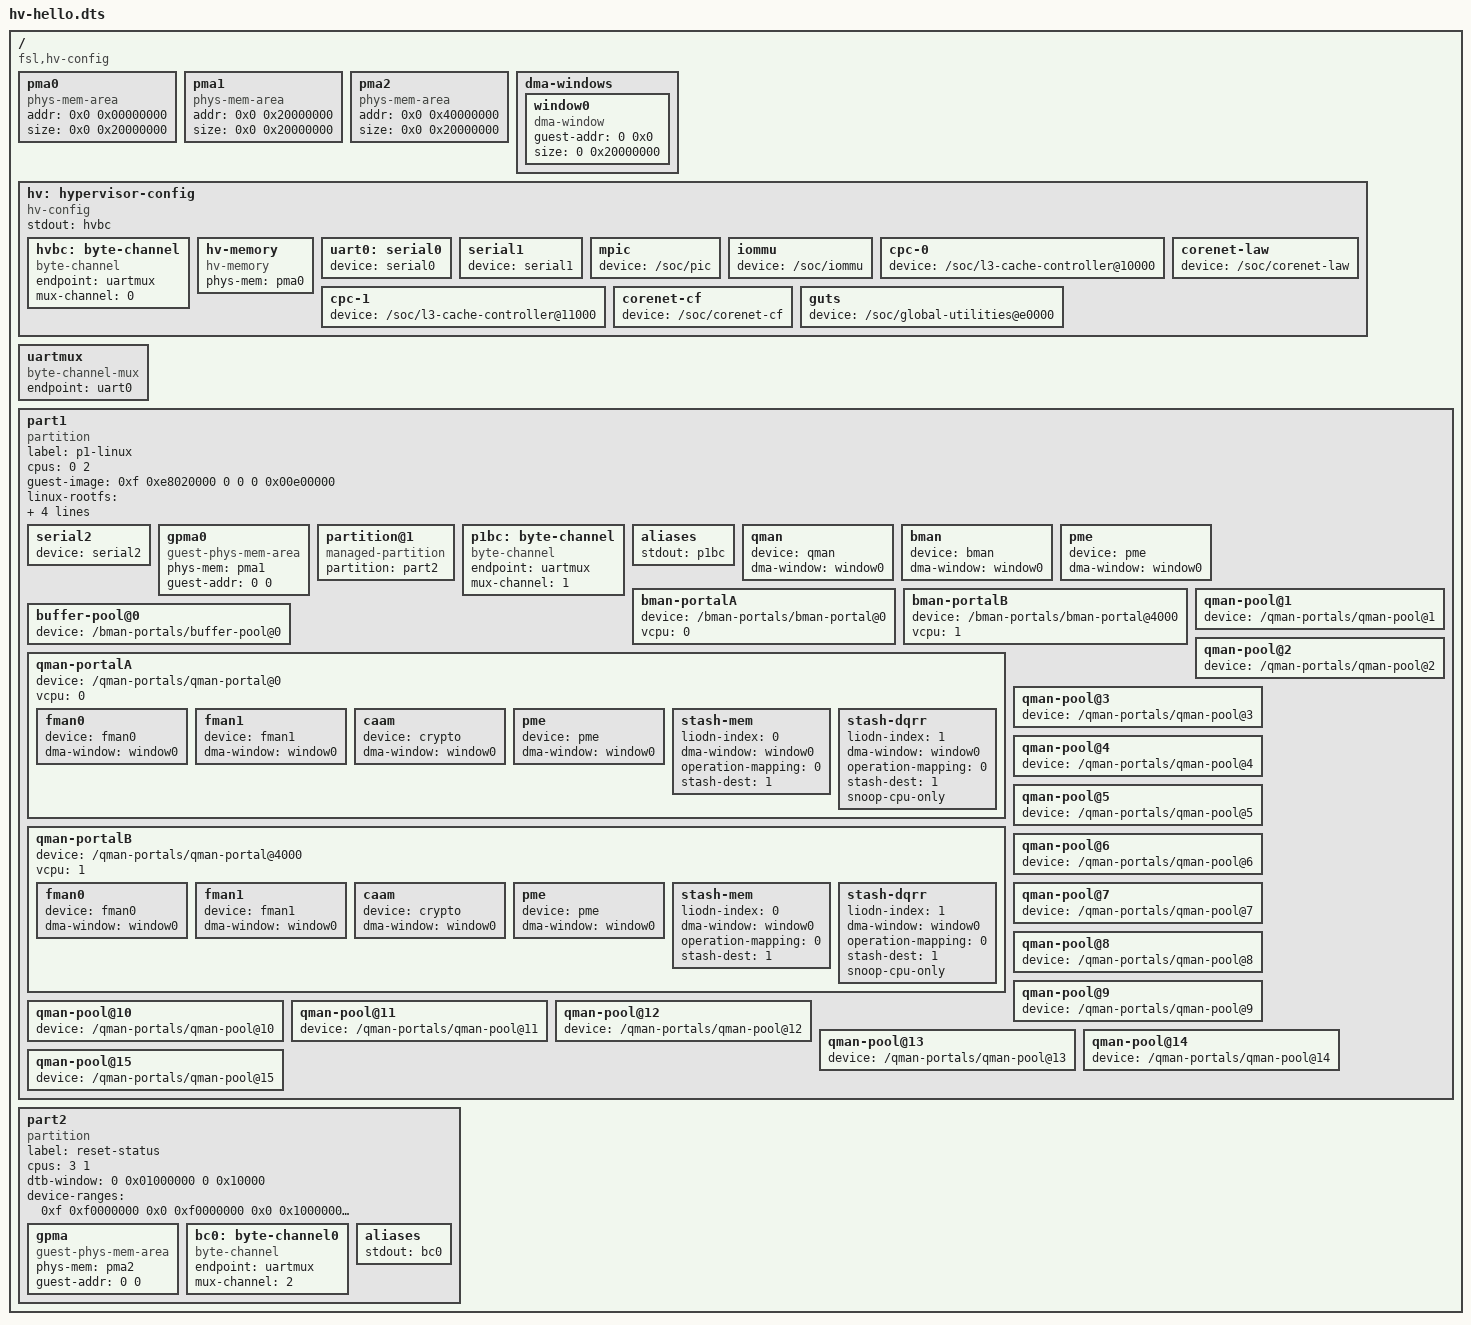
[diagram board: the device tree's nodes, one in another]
/*
 * Copyright (C) 2008-2010 Freescale Semiconductor, Inc.
 *
 * Redistribution and use in source and binary forms, with or without
 * modification, are permitted provided that the following conditions
 * are met:
 * 1. Redistributions of source code must retain the above copyright
 *    notice, this list of conditions and the following disclaimer.
 * 2. Redistributions in binary form must reproduce the above copyright
 *    notice, this list of conditions and the following disclaimer in the
 *    documentation and/or other materials provided with the distribution.
 *
 * THIS SOFTWARE IS PROVIDED BY THE AUTHOR "AS IS" AND ANY EXPRESS OR
 * IMPLIED WARRANTIES, INCLUDING, BUT NOT LIMITED TO, THE IMPLIED WARRANTIES
 * OF MERCHANTABILITY AND FITNESS FOR A PARTICULAR PURPOSE ARE DISCLAIMED.  IN
 * NO EVENT SHALL THE AUTHOR BE LIABLE FOR ANY DIRECT, INDIRECT, INCIDENTAL,
 * SPECIAL, EXEMPLARY, OR CONSEQUENTIAL DAMAGES (INCLUDING, BUT NOT LIMITED
 * TO, PROCUREMENT OF SUBSTITUTE GOODS OR SERVICES; LOSS OF USE, DATA, OR
 * PROFITS; OR BUSINESS INTERRUPTION) HOWEVER CAUSED AND ON ANY THEORY OF
 * LIABILITY, WHETHER IN CONTRACT, STRICT LIABILITY, OR TORT (INCLUDING
 * NEGLIGENCE OR OTHERWISE) ARISING IN ANY WAY OUT OF THE USE OF THIS
 * SOFTWARE, EVEN IF ADVISED OF THE POSSIBILITY OF SUCH DAMAGE.
 */

/dts-v1/;

/ {
	compatible = "fsl,hv-config";

	// =====================================================
	// Physical Memory Areas
	// =====================================================
	pma0:pma0 {
		compatible = "phys-mem-area";
		addr = <0x0 0x00000000>;
		size = <0x0 0x20000000>;  // 512MB
	};

	pma1:pma1 {
		compatible = "phys-mem-area";
		addr = <0x0 0x20000000>;
		size = <0x0 0x20000000>;  // 512MB
	};

	pma2:pma2 {
		compatible = "phys-mem-area";
		addr = <0x0 0x40000000>;
		size = <0x0 0x20000000>;  // 512MB
	};

	dma-windows {
		window0: window0 {
			compatible = "dma-window";
			guest-addr = <0 0x0>;
			size = <0 0x20000000>;
		};
	};

	// =====================================================
	// Hypervisor Config
	// =====================================================
	hv:hypervisor-config {
		compatible = "hv-config";
		stdout = <&hvbc>;

		hvbc: byte-channel {
			compatible = "byte-channel";
			endpoint = <&uartmux>;
			mux-channel = <0>;
		};

		hv-memory {
			compatible = "hv-memory";
			phys-mem = <&pma0>;
		};

		uart0:serial0 {
			device = "serial0";
		};

		serial1:serial1 {
			device = "serial1";
		};

		mpic {
			device = "/soc/pic";
		};

		iommu {
			device = "/soc/iommu";
		};

		cpc-0 {
			device = "/soc/l3-cache-controller@10000";
		};

		cpc-1 {
			device = "/soc/l3-cache-controller@11000";
		};

		corenet-law {
			device = "/soc/corenet-law";
		};

		corenet-cf {
			device = "/soc/corenet-cf";
		};

		guts {
			device = "/soc/global-utilities@e0000";
		};
	};

	uartmux: uartmux {
		compatible = "byte-channel-mux";
		endpoint = <&uart0>;
	};

	// =====================================================
	// Partition 1
	// =====================================================
	part1 {
		compatible = "partition";
		label = "p1-linux";
		cpus = <0 2>;
		guest-image = <0xf 0xe8020000 0 0 0 0x00e00000>;
		linux-rootfs = <0xf 0xe9300000 0 0x01300000 0 0x00f00000>;
		dtb-window = <0 0x1000000 0 0x10000>;

		device-ranges = <0xf 0xf0000000 0x0 0xf0000000 0x0 0x10000000
				 0xc 0x00000000 0x0 0x80000000 0x0 0x20000000
				 0xc 0x20000000 0x0 0xa0000000 0x0 0x20000000
				 0xc 0x40000000 0x0 0xc0000000 0x0 0x20000000>;

		serial2 {
			device = "serial2";
		};

		gpma0 {
			compatible = "guest-phys-mem-area";
			phys-mem = <&pma1>;
			guest-addr = <0 0>;
		};

		partition@1 {
			compatible = "managed-partition";
			partition = <&part2>;
		};

		p1bc: byte-channel {
			compatible = "byte-channel";
			endpoint = <&uartmux>;
			mux-channel = <1>;
		};

		aliases {
			stdout = <&p1bc>;
		};

		qman {
			device = "qman";
			dma-window = <&window0>;
		};

		bman {
			device = "bman";
			dma-window = <&window0>;
		};

		pme {
			device = "pme";
			dma-window = <&window0>;
		};

		bman-portalA {
			device = "/bman-portals/bman-portal@0";
			vcpu = <0>;
		};

		bman-portalB {
			device = "/bman-portals/bman-portal@4000";
			vcpu = <1>;
		};

		buffer-pool@0 {
			device = "/bman-portals/buffer-pool@0";
		};

		qman-portalA {
			device = "/qman-portals/qman-portal@0";
			vcpu = <0>;
			fman0 {
				device = "fman0";
				dma-window = <&window0>;
			};
			fman1 {
				device = "fman1";
				dma-window = <&window0>;
			};
			caam {
				device = "crypto";
				dma-window = <&window0>;
			};
			pme {
				device = "pme";
				dma-window = <&window0>;
			};
			stash-mem {
				liodn-index = <0>;
				dma-window = <&window0>;
				operation-mapping = <0>;  // OMI_QMAN
				stash-dest = <1>;
			};
			stash-dqrr {
				liodn-index = <1>;
				dma-window = <&window0>;
				operation-mapping = <0>;  // OMI_QMAN
				stash-dest = <1>;
				snoop-cpu-only;
			};

		};

		qman-portalB {
			device = "/qman-portals/qman-portal@4000";
			vcpu = <1>;
			fman0 {
				device = "fman0";
				dma-window = <&window0>;
			};
			fman1 {
				device = "fman1";
				dma-window = <&window0>;
			};
			caam {
				device = "crypto";
				dma-window = <&window0>;
			};
			pme {
				device = "pme";
				dma-window = <&window0>;
			};
			stash-mem {
				liodn-index = <0>;
				dma-window = <&window0>;
				operation-mapping = <0>;  // OMI_QMAN
				stash-dest = <1>;
			};
			stash-dqrr {
				liodn-index = <1>;
				dma-window = <&window0>;
				operation-mapping = <0>;  // OMI_QMAN
				stash-dest = <1>;
				snoop-cpu-only;
			};
		};

		qman-pool@1 {
			device = "/qman-portals/qman-pool@1";
		};

		qman-pool@2 {
			device = "/qman-portals/qman-pool@2";
		};

		qman-pool@3 {
			device = "/qman-portals/qman-pool@3";
		};

		qman-pool@4 {
			device = "/qman-portals/qman-pool@4";
		};

		qman-pool@5 {
			device = "/qman-portals/qman-pool@5";
		};

		qman-pool@6 {
			device = "/qman-portals/qman-pool@6";
		};

		qman-pool@7 {
			device = "/qman-portals/qman-pool@7";
		};

		qman-pool@8 {
			device = "/qman-portals/qman-pool@8";
		};

		qman-pool@9 {
			device = "/qman-portals/qman-pool@9";
		};

		qman-pool@10 {
			device = "/qman-portals/qman-pool@10";
		};

		qman-pool@11 {
			device = "/qman-portals/qman-pool@11";
		};

		qman-pool@12 {
			device = "/qman-portals/qman-pool@12";
		};

		qman-pool@13 {
			device = "/qman-portals/qman-pool@13";
		};

		qman-pool@14 {
			device = "/qman-portals/qman-pool@14";
		};

		qman-pool@15 {
			device = "/qman-portals/qman-pool@15";
		};

	};

	// =====================================================
	// Partition 2
	// =====================================================
	part2:part2 {
		compatible = "partition";
		label = "reset-status";
		cpus = <3 1>;
		dtb-window = <0 0x01000000 0 0x10000>;

		device-ranges = <0xf 0xf0000000 0x0 0xf0000000 0x0 0x10000000
				 0xc 0x00000000 0x0 0x80000000 0x0 0x20000000
				 0xc 0x20000000 0x0 0xa0000000 0x0 0x20000000
				 0xc 0x40000000 0x0 0xc0000000 0x0 0x20000000>;

		gpma {
			compatible = "guest-phys-mem-area";
			phys-mem = <&pma2>;
			guest-addr = <0 0>;
		};

		bc0: byte-channel0 {
			compatible = "byte-channel";
			endpoint = <&uartmux>;
			mux-channel = <2>;
		};

		aliases {
			stdout = <&bc0>;
		};
	};

};
